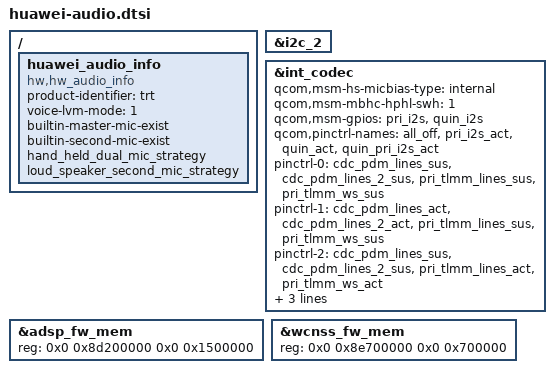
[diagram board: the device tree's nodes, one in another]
/ {
    huawei_audio_info {
        compatible = "hw,hw_audio_info";
        product-identifier = "trt";
        /*disable lvm: set voice-lvm-mode 1*/
        voice-lvm-mode = "1";
        builtin-master-mic-exist;
        builtin-second-mic-exist;
        hand_held_dual_mic_strategy;
        status = "ok";
        loud_speaker_second_mic_strategy;
    };
};

&i2c_2 {
	/delete-node/ wsa881x-i2c-codec@e;
	/delete-node/ wsa881x-i2c-codec@44;
	/delete-node/ wsa881x-i2c-codec@f;
	/delete-node/ wsa881x-i2c-codec@45;
};

&int_codec {
	/delete-property/ qcom,msm-micbias1-ext-cap;
	/delete-property/ qcom,cdc-us-euro-gpios;
	qcom,msm-hs-micbias-type = "internal";
	qcom,msm-mbhc-hphl-swh = <1>;
	qcom,msm-gpios =
		"pri_i2s",
		"quin_i2s";
	qcom,pinctrl-names =
		"all_off",
		"pri_i2s_act",
		"quin_act",
		"quin_pri_i2s_act";
	pinctrl-names =
		"all_off",
		"pri_i2s_act",
		"quin_act",
		"quin_pri_i2s_act";
	pinctrl-0 = <&cdc_pdm_lines_sus
			&cdc_pdm_lines_2_sus
			&pri_tlmm_lines_sus &pri_tlmm_ws_sus>;
	pinctrl-1 = <&cdc_pdm_lines_act
			&cdc_pdm_lines_2_act
			&pri_tlmm_lines_sus &pri_tlmm_ws_sus>;
	pinctrl-2 = <&cdc_pdm_lines_sus
			&cdc_pdm_lines_2_sus
			&pri_tlmm_lines_act &pri_tlmm_ws_act>;
	pinctrl-3 = <&cdc_pdm_lines_act
			&cdc_pdm_lines_2_act
			&pri_tlmm_lines_act &pri_tlmm_ws_act>;
	/delete-property/ pinctrl-4 ;
	/delete-property/ pinctrl-5 ;
	/delete-property/ pinctrl-6;
	/delete-property/ pinctrl-7;

};

&adsp_fw_mem {
	reg = <0x0 0x8d200000 0x0 0x1500000>;
};

&wcnss_fw_mem {
	reg = <0x0 0x8e700000 0x0 0x700000>;
};
